AUTOSAR XML (schema 00046)
package /MICROSAR/Dcm_swc
  5 x mode declaration group:
    DcmControlDtcSetting: category=EXPLICIT_ORDER, initial-mode=ENABLEDTCSETTING, on-transition-value=2
      mode ENABLEDTCSETTING: value=0
      mode DISABLEDTCSETTING: value=1
    DcmEcuReset: category=EXPLICIT_ORDER, initial-mode=NONE, on-transition-value=7
      7 x mode:
        NONE: value=0
        HARD: value=1
        KEYONOFF: value=2
        SOFT: value=3
        JUMPTOBOOTLOADER: value=4
        JUMPTOSYSSUPPLIERBOOTLOADER: value=5
        EXECUTE: value=6
    DcmDiagnosticSessionControl: category=EXPLICIT_ORDER, initial-mode=DEFAULT_SESSION, on-transition-value=255
      4 x mode:
        DEFAULT_SESSION: value=1
        EXTENDED_SESSION: value=3
        EOLDiagnosticSession: value=96
        UFSKeepProgrammingSession: value=111
    DcmCommunicationControl: category=EXPLICIT_ORDER, initial-mode=DCM_ENABLE_RX_TX_NORM, on-transition-value=12
      12 x mode:
        DCM_ENABLE_RX_TX_NORM: value=0
        DCM_ENABLE_RX_DISABLE_TX_NORM: value=1
        DCM_DISABLE_RX_ENABLE_TX_NORM: value=2
        DCM_DISABLE_RX_TX_NORMAL: value=3
        DCM_ENABLE_RX_TX_NM: value=4
        DCM_ENABLE_RX_DISABLE_TX_NM: value=5
        DCM_DISABLE_RX_ENABLE_TX_NM: value=6
        DCM_DISABLE_RX_TX_NM: value=7
        DCM_ENABLE_RX_TX_NORM_NM: value=8
        DCM_ENABLE_RX_DISABLE_TX_NORM_NM: value=9
        DCM_DISABLE_RX_ENABLE_TX_NORM_NM: value=10
        DCM_DISABLE_RX_TX_NORM_NM: value=11
    DcmUserConditionMode: initial-mode=DCM_USER_CONDITON_NOT_OK
      mode DCM_USER_CONDITION_OK
      mode DCM_USER_CONDITON_NOT_OK
  data type mapping set DcmMappingSet  # Contains mapping for ModeDeclarationGroups which are provided by Dcm.
    mode-request-type-maps:
      implementation-data-type=Dcm_ControlDtcSettingType, mode-group=DcmControlDtcSetting
      implementation-data-type=Dcm_EcuResetType, mode-group=DcmEcuReset
      implementation-data-type=Dcm_DiagnosticSessionControlType, mode-group=DcmDiagnosticSessionControl
      implementation-data-type=Dcm_CommunicationModeType, mode-group=DcmCommunicationControl
package /MICROSAR/Dcm_swc/DataTypes
  19 x impl type:
    Dcm_ConfirmationStatusType: compu {0=DCM_RES_POS_OK, 1=DCM_RES_POS_NOT_OK, 2=DCM_RES_NEG_OK, 3=DCM_RES_NEG_NOT_OK}, range raw 0..3, implementation-data-type=uint8
    Dcm_OpStatusType: compu {0=DCM_INITIAL, 1=DCM_PENDING, 2=DCM_CANCEL, 3=DCM_FORCE_RCRRP_OK, 64=DCM_FORCE_RCRRP_NOT_OK}, range raw 0..64, implementation-data-type=uint8
    Dcm_NegativeResponseCodeType:
      compu {0=DCM_E_POSITIVERESPONSE, 16=DCM_E_GENERALREJECT, 17=DCM_E_SERVICENOTSUPPORTED, 18=DCM_E_SUBFUNCTIONNOTSUPPORTED, 19=DCM_E_INCORRECTMESSAGELENGTHORINVALIDFORMAT, 20=DCM_E_RESPONSETOOLONG, 33=DCM_E_BUSYREPEATREQUEST, 34=DCM_E_CONDITIONSNOTCORRECT, 36=DCM_E_REQUESTSEQUENCEERROR, 37=DCM_E_NORESPONSEFROMSUBNETCOMPONENT, 38=DCM_E_FAILUREPREVENTSEXECUTIONOFREQUESTEDACTION, 49=DCM_E_REQUESTOUTOFRANGE, 51=DCM_E_SECURITYACCESSDENIED, 52=DCM_E_AUTHENTICATIONREQUIRED, 53=DCM_E_INVALIDKEY, 54=DCM_E_EXCEEDNUMBEROFATTEMPTS, 55=DCM_E_REQUIREDTIMEDELAYNOTEXPIRED, 80=DCM_E_CVF_INVALIDTIMEPERIOD, 81=DCM_E_CVF_INVALIDSIGNATURE, 82=DCM_E_CVF_INVALIDCHAINOFTRUST, 83=DCM_E_CVF_INVALIDTYPE, 84=DCM_E_CVF_INVALIDFORMAT, 85=DCM_E_CVF_INVALIDCONTENT, 86=DCM_E_CVF_INVALIDSCOPE, 87=DCM_E_CVF_INVALIDCERTIFICATEREVOKED, 88=DCM_E_OWNERSHIPVERIFICATIONFAILED, 89=DCM_E_CHALLENGECALCULATIONFAILED, 112=DCM_E_UPLOADDOWNLOADNOTACCEPTED, 113=DCM_E_TRANSFERDATASUSPENDED, 114=DCM_E_GENERALPROGRAMMINGFAILURE, 115=DCM_E_WRONGBLOCKSEQUENCECOUNTER, 120=DCM_E_REQUESTCORRECTLYRECEIVEDRESPONSEPENDING, 126=DCM_E_SUBFUNCTIONNOTSUPPORTEDINACTIVESESSION, 127=DCM_E_SERVICENOTSUPPORTEDINACTIVESESSION, 129=DCM_E_RPMTOOHIGH, 130=DCM_E_RPMTOOLOW, 131=DCM_E_ENGINEISRUNNING, 132=DCM_E_ENGINEISNOTRUNNING, 133=DCM_E_ENGINERUNTIMETOOLOW, 134=DCM_E_TEMPERATURETOOHIGH, 135=DCM_E_TEMPERATURETOOLOW, 136=DCM_E_VEHICLESPEEDTOOHIGH, 137=DCM_E_VEHICLESPEEDTOOLOW, 138=DCM_E_THROTTLE_PEDALTOOHIGH, 139=DCM_E_THROTTLE_PEDALTOOLOW, 140=DCM_E_TRANSMISSIONRANGENOTINNEUTRAL, 141=DCM_E_TRANSMISSIONRANGENOTINGEAR, 143=DCM_E_BRAKESWITCH_NOTCLOSED, 144=DCM_E_SHIFTERLEVERNOTINPARK, 145=DCM_E_TORQUECONVERTERCLUTCHLOCKED, 146=DCM_E_VOLTAGETOOHIGH, 147=DCM_E_VOLTAGETOOLOW, 240..249=DCM_E_VMSCNC_0..DCM_E_VMSCNC_9, 250=DCM_E_VMSCNC_A, 251=DCM_E_VMSCNC_B, 252=DCM_E_VMSCNC_C, 253=DCM_E_VMSCNC_D, 254=DCM_E_VMSCNC_E}
      range raw 0..254
      implementation-data-type=uint8
    Dcm_ProtocolType: compu {0=DCM_OBD_ON_CAN, 1=DCM_OBD_ON_FLEXRAY, 2=DCM_OBD_ON_IP, 3=DCM_UDS_ON_CAN, 4=DCM_UDS_ON_FLEXRAY, 5=DCM_UDS_ON_IP, 12=DCM_NO_ACTIVE_PROTOCOL, 240..254=DCM_SUPPLIER_1..DCM_SUPPLIER_15}, range raw 0..254, implementation-data-type=uint8
    Dcm_RequestKindType: compu {0=DCM_REQ_KIND_NONE, 1=DCM_REQ_KIND_EXTERNAL, 2=DCM_REQ_KIND_ROE}, range raw 0..2, implementation-data-type=uint8
    Dcm_SecLevelType: compu {0=DCM_SEC_LEV_LOCKED, 1=DCM_SEC_LEV_L1, 49=DCM_SEC_LEV_L49}, range raw 0..49, implementation-data-type=uint8
    Dcm_SesCtrlType: compu {1=DCM_DEFAULT_SESSION, 3=DCM_EXTENDED_DIAGNOSTIC_SESSION, 96=DCM_EOLDiagnosticSession, 111=DCM_UFSKeepProgrammingSession}, range raw 0..111, implementation-data-type=uint8
    Dcm_ControlDtcSettingType: compu {0=DCM_ENUM_ENABLEDTCSETTING, 1=DCM_ENUM_DISABLEDTCSETTING}, range raw 0..255, implementation-data-type=uint8
    Dcm_EcuResetType: compu {0=DCM_ENUM_NONE, 1=DCM_ENUM_HARD, 2=DCM_ENUM_KEYONOFF, 3=DCM_ENUM_SOFT, 4=DCM_ENUM_JUMPTOBOOTLOADER, 5=DCM_ENUM_JUMPTOSYSSUPPLIERBOOTLOADER, 6=DCM_ENUM_EXECUTE}, range raw 0..255, implementation-data-type=uint8
    Dcm_DiagnosticSessionControlType: compu {1=DCM_ENUM_DEFAULT_SESSION, 3=DCM_ENUM_EXTENDED_SESSION, 96=DCM_ENUM_EOLDiagnosticSession, 111=DCM_ENUM_UFSKeepProgrammingSession}, range raw 0..255, implementation-data-type=uint8
    Dcm_CommunicationModeType:
      compu {0=DCM_ENABLE_RX_TX_NORM, 1=DCM_ENABLE_RX_DISABLE_TX_NORM, 2=DCM_DISABLE_RX_ENABLE_TX_NORM, 3=DCM_DISABLE_RX_TX_NORMAL, 4=DCM_ENABLE_RX_TX_NM, 5=DCM_ENABLE_RX_DISABLE_TX_NM, 6=DCM_DISABLE_RX_ENABLE_TX_NM, 7=DCM_DISABLE_RX_TX_NM, 8=DCM_ENABLE_RX_TX_NORM_NM, 9=DCM_ENABLE_RX_DISABLE_TX_NORM_NM, 10=DCM_DISABLE_RX_ENABLE_TX_NORM_NM, 11=DCM_DISABLE_RX_TX_NORM_NM}
      range raw 0..255
      implementation-data-type=uint8
    Dcm_Data4095ByteType: category=ARRAY, sw-calibration-access=READ-ONLY
      element Dcm_Data4095ByteTypeElement: array-size=4095, array-size-semantics=FIXED-SIZE, implementation-data-type=uint8
    Dcm_Data4ByteType: category=ARRAY, sw-calibration-access=READ-ONLY
      element Dcm_Data4ByteTypeElement: array-size=4, array-size-semantics=FIXED-SIZE, implementation-data-type=uint8
    Dcm_Data8ByteType: category=ARRAY, sw-calibration-access=READ-ONLY
      element Dcm_Data8ByteTypeElement: array-size=8, array-size-semantics=FIXED-SIZE, implementation-data-type=uint8
    Dcm_Data20ByteType: category=ARRAY, sw-calibration-access=READ-ONLY
      element Dcm_Data20ByteTypeElement: array-size=20, array-size-semantics=FIXED-SIZE, implementation-data-type=uint8
    Dcm_Data10ByteType: category=ARRAY, sw-calibration-access=READ-ONLY
      element Dcm_Data10ByteTypeElement: array-size=10, array-size-semantics=FIXED-SIZE, implementation-data-type=uint8
    Dcm_Data4000ByteType: category=ARRAY, sw-calibration-access=READ-ONLY
      element Dcm_Data4000ByteTypeElement: array-size=4000, array-size-semantics=FIXED-SIZE, implementation-data-type=uint8
    Dcm_DidSupportedType: compu {0=DCM_DID_SUPPORTED, 1=DCM_DID_NOT_SUPPORTED}, range raw 0..1, implementation-data-type=uint8
    Dcm_Data300ByteType: category=ARRAY, sw-calibration-access=READ-ONLY
      element Dcm_Data300ByteTypeElement: array-size=300, array-size-semantics=FIXED-SIZE, implementation-data-type=uint8
package /MICROSAR/Dcm_swc/Interfaces
  5 x mode switch interface, all with is-service=true, service-kind=DIAGNOSTIC-COMMUNICATION-MANAGER:
    DcmControlDtcSetting
      mode group DcmControlDtcSetting: type=DcmControlDtcSetting
    DcmEcuReset
      mode group DcmEcuReset: type=DcmEcuReset
    DcmDiagnosticSessionControl
      mode group DcmDiagnosticSessionControl: type=DcmDiagnosticSessionControl
    DcmCommunicationControl_ComMConf_ComMChannel_CN_B30_for_SC_CAN_V3_2_c0d6c67b
      mode group DcmCommunicationControl_ComMConf_ComMChannel_CN_B30_for_SC_CAN_V3_2_c0d6c67b: type=DcmCommunicationControl
    Dcm_Read_Mode
      mode group Dcm_Read_Mode: type=DcmUserConditionMode
  29 x client server interface, all with is-service=true, service-kind=DIAGNOSTIC-COMMUNICATION-MANAGER:
    DCMServices
      6 x operation:
        GetActiveProtocol: possible-error=E_OK
          arg ActiveProtocol: type=Dcm_ProtocolType, direction=OUT
        GetSesCtrlType: possible-error=E_OK
          arg SesCtrlType: type=Dcm_SesCtrlType, direction=OUT
        ResetToDefaultSession: possible-error=E_OK
        GetSecurityLevel: possible-error=E_OK
          arg SecLevel: type=Dcm_SecLevelType, direction=OUT
        SetActiveDiagnostic: possible-error=E_OK
          arg active: type=boolean, direction=IN
        GetRequestKind: possible-error=DCMServices/E_NOT_OK
          arg TesterSourceAddress: type=uint16, direction=IN
          arg RequestKind: type=Dcm_RequestKindType, direction=OUT
      error E_OK: error-code=0
      error E_NOT_OK: error-code=1
    ServiceRequestNotification
      operation Indication: possible-error=[ServiceRequestNotification/E_NOT_OK, E_REQUEST_NOT_ACCEPTED]
        6 x arg:
          SID: type=uint8, direction=IN
          RequestData: type=Dcm_Data4095ByteType, direction=IN
          DataSize: type=uint16, direction=IN
          ReqType: type=uint8, direction=IN
          SourceAddress: type=uint16, direction=IN
          ErrorCode: type=Dcm_NegativeResponseCodeType, direction=OUT
      operation Confirmation: possible-error=ServiceRequestNotification/E_NOT_OK
        4 x arg, all with direction=IN:
          SID: type=uint8
          ReqType: type=uint8
          SourceAddress: type=uint16
          ConfirmationStatus: type=Dcm_ConfirmationStatusType
      error E_NOT_OK: error-code=1
      error E_REQUEST_NOT_ACCEPTED: error-code=8
    SecurityAccess_UnlockedL1
      4 x operation:
        GetSeed: possible-error=[SecurityAccess_UnlockedL1/E_NOT_OK, SecurityAccess_UnlockedL1/DCM_E_PENDING]
          arg OpStatus: type=Dcm_OpStatusType, direction=IN
          arg Seed: type=Dcm_Data4ByteType, direction=OUT
          arg ErrorCode: type=Dcm_NegativeResponseCodeType, direction=OUT
        CompareKey: possible-error=[SecurityAccess_UnlockedL1/E_NOT_OK, SecurityAccess_UnlockedL1/DCM_E_PENDING, SecurityAccess_UnlockedL1/DCM_E_COMPARE_KEY_FAILED]
          arg Key: type=Dcm_Data4ByteType, direction=IN
          arg OpStatus: type=Dcm_OpStatusType, direction=IN
          arg ErrorCode: type=Dcm_NegativeResponseCodeType, direction=OUT
        GetSecurityAttemptCounter: possible-error=[SecurityAccess_UnlockedL1/E_NOT_OK, SecurityAccess_UnlockedL1/DCM_E_PENDING]
          arg OpStatus: type=Dcm_OpStatusType, direction=IN
          arg AttemptCounter: type=uint8, direction=OUT
        SetSecurityAttemptCounter: possible-error=[SecurityAccess_UnlockedL1/E_NOT_OK, SecurityAccess_UnlockedL1/DCM_E_PENDING]
          arg OpStatus: type=Dcm_OpStatusType, direction=IN
          arg AttemptCounter: type=uint8, direction=IN
      error E_NOT_OK: error-code=1
      error DCM_E_PENDING: error-code=10
      error DCM_E_COMPARE_KEY_FAILED: error-code=11
    SecurityAccess_Level_EOL_Unlocked
      4 x operation:
        GetSeed: possible-error=[SecurityAccess_Level_EOL_Unlocked/E_NOT_OK, SecurityAccess_Level_EOL_Unlocked/DCM_E_PENDING]
          arg OpStatus: type=Dcm_OpStatusType, direction=IN
          arg Seed: type=Dcm_Data4ByteType, direction=OUT
          arg ErrorCode: type=Dcm_NegativeResponseCodeType, direction=OUT
        CompareKey: possible-error=[SecurityAccess_Level_EOL_Unlocked/E_NOT_OK, SecurityAccess_Level_EOL_Unlocked/DCM_E_PENDING, SecurityAccess_Level_EOL_Unlocked/DCM_E_COMPARE_KEY_FAILED]
          arg Key: type=Dcm_Data8ByteType, direction=IN
          arg OpStatus: type=Dcm_OpStatusType, direction=IN
          arg ErrorCode: type=Dcm_NegativeResponseCodeType, direction=OUT
        GetSecurityAttemptCounter: possible-error=[SecurityAccess_Level_EOL_Unlocked/E_NOT_OK, SecurityAccess_Level_EOL_Unlocked/DCM_E_PENDING]
          arg OpStatus: type=Dcm_OpStatusType, direction=IN
          arg AttemptCounter: type=uint8, direction=OUT
        SetSecurityAttemptCounter: possible-error=[SecurityAccess_Level_EOL_Unlocked/E_NOT_OK, SecurityAccess_Level_EOL_Unlocked/DCM_E_PENDING]
          arg OpStatus: type=Dcm_OpStatusType, direction=IN
          arg AttemptCounter: type=uint8, direction=IN
      error E_NOT_OK: error-code=1
      error DCM_E_PENDING: error-code=10
      error DCM_E_COMPARE_KEY_FAILED: error-code=11
    RoutineServices_CheckEthernetIPPINGFunction
      operation Start: possible-error=[RoutineServices_CheckEthernetIPPINGFunction/E_NOT_OK, RoutineServices_CheckEthernetIPPINGFunction/DCM_E_PENDING, RoutineServices_CheckEthernetIPPINGFunction/DCM_E_FORCE_RCRRP]
        arg In_Start: type=uint32, direction=IN
        arg OpStatus: type=Dcm_OpStatusType, direction=IN
        arg ErrorCode: type=Dcm_NegativeResponseCodeType, direction=OUT
      operation RequestResults: possible-error=[RoutineServices_CheckEthernetIPPINGFunction/E_NOT_OK, RoutineServices_CheckEthernetIPPINGFunction/DCM_E_PENDING, RoutineServices_CheckEthernetIPPINGFunction/DCM_E_FORCE_RCRRP]
        arg OpStatus: type=Dcm_OpStatusType, direction=IN
        arg Out_0xF003: type=uint8, direction=OUT
        arg ErrorCode: type=Dcm_NegativeResponseCodeType, direction=OUT
      error E_NOT_OK: error-code=1
      error DCM_E_PENDING: error-code=10
      error DCM_E_FORCE_RCRRP: error-code=12
    RoutineServices_IVITouchTest
      operation Start: possible-error=[RoutineServices_IVITouchTest/E_NOT_OK, RoutineServices_IVITouchTest/DCM_E_PENDING, RoutineServices_IVITouchTest/DCM_E_FORCE_RCRRP]
        arg OpStatus: type=Dcm_OpStatusType, direction=IN
        arg Out_0xF004: type=uint8, direction=OUT
        arg ErrorCode: type=Dcm_NegativeResponseCodeType, direction=OUT
      operation RequestResults: possible-error=[RoutineServices_IVITouchTest/E_NOT_OK, RoutineServices_IVITouchTest/DCM_E_PENDING, RoutineServices_IVITouchTest/DCM_E_FORCE_RCRRP]
        arg OpStatus: type=Dcm_OpStatusType, direction=IN
        arg Out_0xF004: type=Dcm_Data20ByteType, direction=OUT
        arg ErrorCode: type=Dcm_NegativeResponseCodeType, direction=OUT
      error E_NOT_OK: error-code=1
      error DCM_E_PENDING: error-code=10
      error DCM_E_FORCE_RCRRP: error-code=12
    RoutineServices_AVMRegister
      operation Start: possible-error=[RoutineServices_AVMRegister/E_NOT_OK, RoutineServices_AVMRegister/DCM_E_PENDING, RoutineServices_AVMRegister/DCM_E_FORCE_RCRRP]
        arg OpStatus: type=Dcm_OpStatusType, direction=IN
        arg Out_AVMRegister: type=uint8, direction=OUT
        arg ErrorCode: type=Dcm_NegativeResponseCodeType, direction=OUT
      operation RequestResults: possible-error=[RoutineServices_AVMRegister/E_NOT_OK, RoutineServices_AVMRegister/DCM_E_PENDING, RoutineServices_AVMRegister/DCM_E_FORCE_RCRRP]
        arg OpStatus: type=Dcm_OpStatusType, direction=IN
        arg Out_AVMRegister: type=uint8, direction=OUT
        arg ErrorCode: type=Dcm_NegativeResponseCodeType, direction=OUT
      error E_NOT_OK: error-code=1
      error DCM_E_PENDING: error-code=10
      error DCM_E_FORCE_RCRRP: error-code=12
    RoutineServices_AMPCalibration
      operation Start: possible-error=[RoutineServices_AMPCalibration/E_NOT_OK, RoutineServices_AMPCalibration/DCM_E_PENDING, RoutineServices_AMPCalibration/DCM_E_FORCE_RCRRP]
        arg OpStatus: type=Dcm_OpStatusType, direction=IN
        arg Out_RoutineStatusRecord: type=uint8, direction=OUT
        arg ErrorCode: type=Dcm_NegativeResponseCodeType, direction=OUT
      operation RequestResults: possible-error=[RoutineServices_AMPCalibration/E_NOT_OK, RoutineServices_AMPCalibration/DCM_E_PENDING, RoutineServices_AMPCalibration/DCM_E_FORCE_RCRRP]
        arg OpStatus: type=Dcm_OpStatusType, direction=IN
        arg Out_AmpValue: type=Dcm_Data10ByteType, direction=OUT
        arg ErrorCode: type=Dcm_NegativeResponseCodeType, direction=OUT
      error E_NOT_OK: error-code=1
      error DCM_E_PENDING: error-code=10
      error DCM_E_FORCE_RCRRP: error-code=12
    RoutineServices_PhyTestMode
      operation Start: possible-error=[RoutineServices_PhyTestMode/E_NOT_OK, RoutineServices_PhyTestMode/DCM_E_PENDING, RoutineServices_PhyTestMode/DCM_E_FORCE_RCRRP]
        4 x arg:
          In_PortNumber: type=uint8, direction=IN
          In_TestMode: type=uint8, direction=IN
          OpStatus: type=Dcm_OpStatusType, direction=IN
          ErrorCode: type=Dcm_NegativeResponseCodeType, direction=OUT
      error E_NOT_OK: error-code=1
      error DCM_E_PENDING: error-code=10
      error DCM_E_FORCE_RCRRP: error-code=12
    RoutineServices_CableDiagnostics
      operation Start: possible-error=[RoutineServices_CableDiagnostics/E_NOT_OK, RoutineServices_CableDiagnostics/DCM_E_PENDING, RoutineServices_CableDiagnostics/DCM_E_FORCE_RCRRP]
        4 x arg:
          In_CableDiagnosticsControl: type=uint8, direction=IN
          OpStatus: type=Dcm_OpStatusType, direction=IN
          Out_Result: type=uint8, direction=OUT
          ErrorCode: type=Dcm_NegativeResponseCodeType, direction=OUT
      error E_NOT_OK: error-code=1
      error DCM_E_PENDING: error-code=10
      error DCM_E_FORCE_RCRRP: error-code=12
    RoutineServices_ResetSwitchStatistics
      operation Start: possible-error=[RoutineServices_ResetSwitchStatistics/E_NOT_OK, RoutineServices_ResetSwitchStatistics/DCM_E_PENDING, RoutineServices_ResetSwitchStatistics/DCM_E_FORCE_RCRRP]
        arg OpStatus: type=Dcm_OpStatusType, direction=IN
        arg ErrorCode: type=Dcm_NegativeResponseCodeType, direction=OUT
      error E_NOT_OK: error-code=1
      error DCM_E_PENDING: error-code=10
      error DCM_E_FORCE_RCRRP: error-code=12
    RoutineServices_AVMEnvironmentCheck
      operation Start: possible-error=[RoutineServices_AVMEnvironmentCheck/E_NOT_OK, RoutineServices_AVMEnvironmentCheck/DCM_E_PENDING, RoutineServices_AVMEnvironmentCheck/DCM_E_FORCE_RCRRP]
        arg OpStatus: type=Dcm_OpStatusType, direction=IN
        arg ErrorCode: type=Dcm_NegativeResponseCodeType, direction=OUT
      operation RequestResults: possible-error=[RoutineServices_AVMEnvironmentCheck/E_NOT_OK, RoutineServices_AVMEnvironmentCheck/DCM_E_PENDING, RoutineServices_AVMEnvironmentCheck/DCM_E_FORCE_RCRRP]
        arg OpStatus: type=Dcm_OpStatusType, direction=IN
        arg Out_AVMEnvironmentCheckResult: type=uint8, direction=OUT
        arg ErrorCode: type=Dcm_NegativeResponseCodeType, direction=OUT
      error E_NOT_OK: error-code=1
      error DCM_E_PENDING: error-code=10
      error DCM_E_FORCE_RCRRP: error-code=12
    RoutineServices_AVMAutoCalibration
      operation Start: possible-error=[RoutineServices_AVMAutoCalibration/E_NOT_OK, RoutineServices_AVMAutoCalibration/DCM_E_PENDING, RoutineServices_AVMAutoCalibration/DCM_E_FORCE_RCRRP]
        arg OpStatus: type=Dcm_OpStatusType, direction=IN
        arg ErrorCode: type=Dcm_NegativeResponseCodeType, direction=OUT
      operation RequestResults: possible-error=[RoutineServices_AVMAutoCalibration/E_NOT_OK, RoutineServices_AVMAutoCalibration/DCM_E_PENDING, RoutineServices_AVMAutoCalibration/DCM_E_FORCE_RCRRP]
        arg OpStatus: type=Dcm_OpStatusType, direction=IN
        arg Out_AVMCalibrationResult: type=uint8, direction=OUT
        arg ErrorCode: type=Dcm_NegativeResponseCodeType, direction=OUT
      error E_NOT_OK: error-code=1
      error DCM_E_PENDING: error-code=10
      error DCM_E_FORCE_RCRRP: error-code=12
    RoutineServices_AVMManualCalibration
      operation Start: possible-error=[RoutineServices_AVMManualCalibration/E_NOT_OK, RoutineServices_AVMManualCalibration/DCM_E_PENDING, RoutineServices_AVMManualCalibration/DCM_E_FORCE_RCRRP]
        arg OpStatus: type=Dcm_OpStatusType, direction=IN
        arg ErrorCode: type=Dcm_NegativeResponseCodeType, direction=OUT
      operation Stop: possible-error=[RoutineServices_AVMManualCalibration/E_NOT_OK, RoutineServices_AVMManualCalibration/DCM_E_PENDING, RoutineServices_AVMManualCalibration/DCM_E_FORCE_RCRRP]
        arg OpStatus: type=Dcm_OpStatusType, direction=IN
        arg ErrorCode: type=Dcm_NegativeResponseCodeType, direction=OUT
      operation RequestResults: possible-error=[RoutineServices_AVMManualCalibration/E_NOT_OK, RoutineServices_AVMManualCalibration/DCM_E_PENDING, RoutineServices_AVMManualCalibration/DCM_E_FORCE_RCRRP]
        arg OpStatus: type=Dcm_OpStatusType, direction=IN
        arg Out_ManualCalibrationResult: type=uint8, direction=OUT
        arg ErrorCode: type=Dcm_NegativeResponseCodeType, direction=OUT
      error E_NOT_OK: error-code=1
      error DCM_E_PENDING: error-code=10
      error DCM_E_FORCE_RCRRP: error-code=12
    RoutineServices_AVMManualViewSelect
      operation Start: possible-error=[RoutineServices_AVMManualViewSelect/E_NOT_OK, RoutineServices_AVMManualViewSelect/DCM_E_PENDING, RoutineServices_AVMManualViewSelect/DCM_E_FORCE_RCRRP]
        arg In_AVMManualViewSelect: type=uint8, direction=IN
        arg OpStatus: type=Dcm_OpStatusType, direction=IN
        arg ErrorCode: type=Dcm_NegativeResponseCodeType, direction=OUT
      operation RequestResults: possible-error=[RoutineServices_AVMManualViewSelect/E_NOT_OK, RoutineServices_AVMManualViewSelect/DCM_E_PENDING, RoutineServices_AVMManualViewSelect/DCM_E_FORCE_RCRRP]
        arg OpStatus: type=Dcm_OpStatusType, direction=IN
        arg Out_AVMEnvironmentCheckResult: type=uint8, direction=OUT
        arg ErrorCode: type=Dcm_NegativeResponseCodeType, direction=OUT
      error E_NOT_OK: error-code=1
      error DCM_E_PENDING: error-code=10
      error DCM_E_FORCE_RCRRP: error-code=12
    RoutineServices_AVMManualConerSelect
      operation Start: possible-error=[RoutineServices_AVMManualConerSelect/E_NOT_OK, RoutineServices_AVMManualConerSelect/DCM_E_PENDING, RoutineServices_AVMManualConerSelect/DCM_E_FORCE_RCRRP]
        arg In_AVMManualConerSelect: type=uint8, direction=IN
        arg OpStatus: type=Dcm_OpStatusType, direction=IN
        arg ErrorCode: type=Dcm_NegativeResponseCodeType, direction=OUT
      operation RequestResults: possible-error=[RoutineServices_AVMManualConerSelect/E_NOT_OK, RoutineServices_AVMManualConerSelect/DCM_E_PENDING, RoutineServices_AVMManualConerSelect/DCM_E_FORCE_RCRRP]
        arg OpStatus: type=Dcm_OpStatusType, direction=IN
        arg Out_AVMEnvironmentCheckResult: type=uint8, direction=OUT
        arg ErrorCode: type=Dcm_NegativeResponseCodeType, direction=OUT
      error E_NOT_OK: error-code=1
      error DCM_E_PENDING: error-code=10
      error DCM_E_FORCE_RCRRP: error-code=12
    RoutineServices_AVMManualConerMove
      operation Start: possible-error=[RoutineServices_AVMManualConerMove/E_NOT_OK, RoutineServices_AVMManualConerMove/DCM_E_PENDING, RoutineServices_AVMManualConerMove/DCM_E_FORCE_RCRRP]
        arg In_AVMManualConerMove: type=uint8, direction=IN
        arg OpStatus: type=Dcm_OpStatusType, direction=IN
        arg ErrorCode: type=Dcm_NegativeResponseCodeType, direction=OUT
      operation RequestResults: possible-error=[RoutineServices_AVMManualConerMove/E_NOT_OK, RoutineServices_AVMManualConerMove/DCM_E_PENDING, RoutineServices_AVMManualConerMove/DCM_E_FORCE_RCRRP]
        arg OpStatus: type=Dcm_OpStatusType, direction=IN
        arg Out_AVMManualConerMoveResult: type=uint8, direction=OUT
        arg ErrorCode: type=Dcm_NegativeResponseCodeType, direction=OUT
      error E_NOT_OK: error-code=1
      error DCM_E_PENDING: error-code=10
      error DCM_E_FORCE_RCRRP: error-code=12
    RoutineServices_AVMManualCorrectValue
      operation Start: possible-error=[RoutineServices_AVMManualCorrectValue/E_NOT_OK, RoutineServices_AVMManualCorrectValue/DCM_E_PENDING, RoutineServices_AVMManualCorrectValue/DCM_E_FORCE_RCRRP]
        arg OpStatus: type=Dcm_OpStatusType, direction=IN
        arg ErrorCode: type=Dcm_NegativeResponseCodeType, direction=OUT
      operation RequestResults: possible-error=[RoutineServices_AVMManualCorrectValue/E_NOT_OK, RoutineServices_AVMManualCorrectValue/DCM_E_PENDING, RoutineServices_AVMManualCorrectValue/DCM_E_FORCE_RCRRP]
        arg OpStatus: type=Dcm_OpStatusType, direction=IN
        arg Out_AVMManualCorrectValue: type=uint8, direction=OUT
        arg ErrorCode: type=Dcm_NegativeResponseCodeType, direction=OUT
      error E_NOT_OK: error-code=1
      error DCM_E_PENDING: error-code=10
      error DCM_E_FORCE_RCRRP: error-code=12
    RoutineServices_SystemRecovery
      operation Start: possible-error=[RoutineServices_SystemRecovery/E_NOT_OK, RoutineServices_SystemRecovery/DCM_E_PENDING, RoutineServices_SystemRecovery/DCM_E_FORCE_RCRRP]
        arg OpStatus: type=Dcm_OpStatusType, direction=IN
        arg Out_SystemRcvrySts: type=uint8, direction=OUT
        arg ErrorCode: type=Dcm_NegativeResponseCodeType, direction=OUT
      error E_NOT_OK: error-code=1
      error DCM_E_PENDING: error-code=10
      error DCM_E_FORCE_RCRRP: error-code=12
    RoutineServices_ODOReset
      operation Start: possible-error=[RoutineServices_ODOReset/E_NOT_OK, RoutineServices_ODOReset/DCM_E_PENDING, RoutineServices_ODOReset/DCM_E_FORCE_RCRRP]
        arg OpStatus: type=Dcm_OpStatusType, direction=IN
        arg ErrorCode: type=Dcm_NegativeResponseCodeType, direction=OUT
      operation RequestResults: possible-error=[RoutineServices_ODOReset/E_NOT_OK, RoutineServices_ODOReset/DCM_E_PENDING, RoutineServices_ODOReset/DCM_E_FORCE_RCRRP]
        arg OpStatus: type=Dcm_OpStatusType, direction=IN
        arg Out_OdoResetResult: type=uint8, direction=OUT
        arg ErrorCode: type=Dcm_NegativeResponseCodeType, direction=OUT
      error E_NOT_OK: error-code=1
      error DCM_E_PENDING: error-code=10
      error DCM_E_FORCE_RCRRP: error-code=12
    DataServices_VehicleModel_VehicleModel
      operation ReadData: possible-error=[DataServices_VehicleModel_VehicleModel/E_NOT_OK, DataServices_VehicleModel_VehicleModel/DCM_E_PENDING]
        arg OpStatus: type=Dcm_OpStatusType, direction=IN
        arg Data: type=Dcm_Data20ByteType, direction=OUT
      operation ConditionCheckRead: possible-error=[DataServices_VehicleModel_VehicleModel/E_NOT_OK, DataServices_VehicleModel_VehicleModel/DCM_E_PENDING]
        arg OpStatus: type=Dcm_OpStatusType, direction=IN
        arg ErrorCode: type=Dcm_NegativeResponseCodeType, direction=OUT
      operation WriteData: possible-error=[DataServices_VehicleModel_VehicleModel/E_NOT_OK, DataServices_VehicleModel_VehicleModel/DCM_E_PENDING]
        arg Data: type=Dcm_Data20ByteType, direction=IN
        arg OpStatus: type=Dcm_OpStatusType, direction=IN
        arg ErrorCode: type=Dcm_NegativeResponseCodeType, direction=OUT
      error E_NOT_OK: error-code=1
      error DCM_E_PENDING: error-code=10
    RoutineServices_ConfigureFrontCamerParameters
      operation Start: possible-error=[RoutineServices_ConfigureFrontCamerParameters/E_NOT_OK, RoutineServices_ConfigureFrontCamerParameters/DCM_E_PENDING, RoutineServices_ConfigureFrontCamerParameters/DCM_E_FORCE_RCRRP]
        arg OpStatus: type=Dcm_OpStatusType, direction=IN
        arg ErrorCode: type=Dcm_NegativeResponseCodeType, direction=OUT
      operation RequestResults: possible-error=[RoutineServices_ConfigureFrontCamerParameters/E_NOT_OK, RoutineServices_ConfigureFrontCamerParameters/DCM_E_PENDING, RoutineServices_ConfigureFrontCamerParameters/DCM_E_FORCE_RCRRP]
        arg OpStatus: type=Dcm_OpStatusType, direction=IN
        arg DcmDspRoutineRequestResOutSignal: type=uint8, direction=OUT
        arg ErrorCode: type=Dcm_NegativeResponseCodeType, direction=OUT
      error E_NOT_OK: error-code=1
      error DCM_E_PENDING: error-code=10
      error DCM_E_FORCE_RCRRP: error-code=12
    RoutineServices_ConfigureRearCamerParameters
      operation Start: possible-error=[RoutineServices_ConfigureRearCamerParameters/E_NOT_OK, RoutineServices_ConfigureRearCamerParameters/DCM_E_PENDING, RoutineServices_ConfigureRearCamerParameters/DCM_E_FORCE_RCRRP]
        arg OpStatus: type=Dcm_OpStatusType, direction=IN
        arg ErrorCode: type=Dcm_NegativeResponseCodeType, direction=OUT
      operation RequestResults: possible-error=[RoutineServices_ConfigureRearCamerParameters/E_NOT_OK, RoutineServices_ConfigureRearCamerParameters/DCM_E_PENDING, RoutineServices_ConfigureRearCamerParameters/DCM_E_FORCE_RCRRP]
        arg OpStatus: type=Dcm_OpStatusType, direction=IN
        arg DcmDspRoutineRequestResOutSignal: type=uint8, direction=OUT
        arg ErrorCode: type=Dcm_NegativeResponseCodeType, direction=OUT
      error E_NOT_OK: error-code=1
      error DCM_E_PENDING: error-code=10
      error DCM_E_FORCE_RCRRP: error-code=12
    RoutineServices_ConfigureLeftCamerParameters
      operation Start: possible-error=[RoutineServices_ConfigureLeftCamerParameters/E_NOT_OK, RoutineServices_ConfigureLeftCamerParameters/DCM_E_PENDING, RoutineServices_ConfigureLeftCamerParameters/DCM_E_FORCE_RCRRP]
        arg OpStatus: type=Dcm_OpStatusType, direction=IN
        arg ErrorCode: type=Dcm_NegativeResponseCodeType, direction=OUT
      operation RequestResults: possible-error=[RoutineServices_ConfigureLeftCamerParameters/E_NOT_OK, RoutineServices_ConfigureLeftCamerParameters/DCM_E_PENDING, RoutineServices_ConfigureLeftCamerParameters/DCM_E_FORCE_RCRRP]
        arg OpStatus: type=Dcm_OpStatusType, direction=IN
        arg DcmDspRoutineRequestResOutSignal: type=uint8, direction=OUT
        arg ErrorCode: type=Dcm_NegativeResponseCodeType, direction=OUT
      error E_NOT_OK: error-code=1
      error DCM_E_PENDING: error-code=10
      error DCM_E_FORCE_RCRRP: error-code=12
    RoutineServices_ConfigureRightCamerParameters
      operation Start: possible-error=[RoutineServices_ConfigureRightCamerParameters/E_NOT_OK, RoutineServices_ConfigureRightCamerParameters/DCM_E_PENDING, RoutineServices_ConfigureRightCamerParameters/DCM_E_FORCE_RCRRP]
        arg OpStatus: type=Dcm_OpStatusType, direction=IN
        arg ErrorCode: type=Dcm_NegativeResponseCodeType, direction=OUT
      operation RequestResults: possible-error=[RoutineServices_ConfigureRightCamerParameters/E_NOT_OK, RoutineServices_ConfigureRightCamerParameters/DCM_E_PENDING, RoutineServices_ConfigureRightCamerParameters/DCM_E_FORCE_RCRRP]
        arg OpStatus: type=Dcm_OpStatusType, direction=IN
        arg DcmDspRoutineRequestResOutSignal: type=uint8, direction=OUT
        arg ErrorCode: type=Dcm_NegativeResponseCodeType, direction=OUT
      error E_NOT_OK: error-code=1
      error DCM_E_PENDING: error-code=10
      error DCM_E_FORCE_RCRRP: error-code=12
    DataServices_DIDRange_DidRangeEol1
      operation ReadDidData: possible-error=[DataServices_DIDRange_DidRangeEol1/E_NOT_OK, DataServices_DIDRange_DidRangeEol1/DCM_E_PENDING]
        5 x arg:
          DID: type=uint16, direction=IN
          Data: type=Dcm_Data4000ByteType, direction=OUT
          OpStatus: type=Dcm_OpStatusType, direction=IN
          DataLength: type=uint16, direction=OUT
          ErrorCode: type=Dcm_NegativeResponseCodeType, direction=OUT
      operation WriteDidData: possible-error=[DataServices_DIDRange_DidRangeEol1/E_NOT_OK, DataServices_DIDRange_DidRangeEol1/DCM_E_PENDING]
        5 x arg:
          DID: type=uint16, direction=IN
          Data: type=Dcm_Data4000ByteType, direction=IN
          OpStatus: type=Dcm_OpStatusType, direction=IN
          DataLength: type=uint16, direction=IN
          ErrorCode: type=Dcm_NegativeResponseCodeType, direction=OUT
      operation IsDidAvailable: possible-error=[DataServices_DIDRange_DidRangeEol1/E_NOT_OK, DataServices_DIDRange_DidRangeEol1/DCM_E_PENDING]
        arg DID: type=uint16, direction=IN
        arg OpStatus: type=Dcm_OpStatusType, direction=IN
        arg supported: type=Dcm_DidSupportedType, direction=OUT
      error E_NOT_OK: error-code=1
      error DCM_E_PENDING: error-code=10
    DataServices_DIDRange_DidRangeDiag1
      operation ReadDidData: possible-error=[DataServices_DIDRange_DidRangeDiag1/E_NOT_OK, DataServices_DIDRange_DidRangeDiag1/DCM_E_PENDING]
        5 x arg:
          DID: type=uint16, direction=IN
          Data: type=Dcm_Data4000ByteType, direction=OUT
          OpStatus: type=Dcm_OpStatusType, direction=IN
          DataLength: type=uint16, direction=OUT
          ErrorCode: type=Dcm_NegativeResponseCodeType, direction=OUT
      operation WriteDidData: possible-error=[DataServices_DIDRange_DidRangeDiag1/E_NOT_OK, DataServices_DIDRange_DidRangeDiag1/DCM_E_PENDING]
        5 x arg:
          DID: type=uint16, direction=IN
          Data: type=Dcm_Data4000ByteType, direction=IN
          OpStatus: type=Dcm_OpStatusType, direction=IN
          DataLength: type=uint16, direction=IN
          ErrorCode: type=Dcm_NegativeResponseCodeType, direction=OUT
      operation IsDidAvailable: possible-error=[DataServices_DIDRange_DidRangeDiag1/E_NOT_OK, DataServices_DIDRange_DidRangeDiag1/DCM_E_PENDING]
        arg DID: type=uint16, direction=IN
        arg OpStatus: type=Dcm_OpStatusType, direction=IN
        arg supported: type=Dcm_DidSupportedType, direction=OUT
      error E_NOT_OK: error-code=1
      error DCM_E_PENDING: error-code=10
    DataServices_DIDRange_DidRangeDiag2
      operation ReadDidData: possible-error=[DataServices_DIDRange_DidRangeDiag2/E_NOT_OK, DataServices_DIDRange_DidRangeDiag2/DCM_E_PENDING]
        5 x arg:
          DID: type=uint16, direction=IN
          Data: type=Dcm_Data300ByteType, direction=OUT
          OpStatus: type=Dcm_OpStatusType, direction=IN
          DataLength: type=uint16, direction=OUT
          ErrorCode: type=Dcm_NegativeResponseCodeType, direction=OUT
      operation WriteDidData: possible-error=[DataServices_DIDRange_DidRangeDiag2/E_NOT_OK, DataServices_DIDRange_DidRangeDiag2/DCM_E_PENDING]
        5 x arg:
          DID: type=uint16, direction=IN
          Data: type=Dcm_Data300ByteType, direction=IN
          OpStatus: type=Dcm_OpStatusType, direction=IN
          DataLength: type=uint16, direction=IN
          ErrorCode: type=Dcm_NegativeResponseCodeType, direction=OUT
      operation IsDidAvailable: possible-error=[DataServices_DIDRange_DidRangeDiag2/E_NOT_OK, DataServices_DIDRange_DidRangeDiag2/DCM_E_PENDING]
        arg DID: type=uint16, direction=IN
        arg OpStatus: type=Dcm_OpStatusType, direction=IN
        arg supported: type=Dcm_DidSupportedType, direction=OUT
      error E_NOT_OK: error-code=1
      error DCM_E_PENDING: error-code=10
    RoutineServices_RequestCertificateStatus
      operation Start: possible-error=[RoutineServices_RequestCertificateStatus/E_NOT_OK, RoutineServices_RequestCertificateStatus/DCM_E_PENDING, RoutineServices_RequestCertificateStatus/DCM_E_FORCE_RCRRP]
        arg OpStatus: type=Dcm_OpStatusType, direction=IN
        arg ErrorCode: type=Dcm_NegativeResponseCodeType, direction=OUT
      operation RequestResults: possible-error=[RoutineServices_RequestCertificateStatus/E_NOT_OK, RoutineServices_RequestCertificateStatus/DCM_E_PENDING, RoutineServices_RequestCertificateStatus/DCM_E_FORCE_RCRRP]
        arg OpStatus: type=Dcm_OpStatusType, direction=IN
        arg DcmDspRoutineRequestResOutSignal: type=uint8, direction=OUT
        arg ErrorCode: type=Dcm_NegativeResponseCodeType, direction=OUT
      error E_NOT_OK: error-code=1
      error DCM_E_PENDING: error-code=10
      error DCM_E_FORCE_RCRRP: error-code=12
package /MICROSAR/Dcm_swc/ComponentTypes
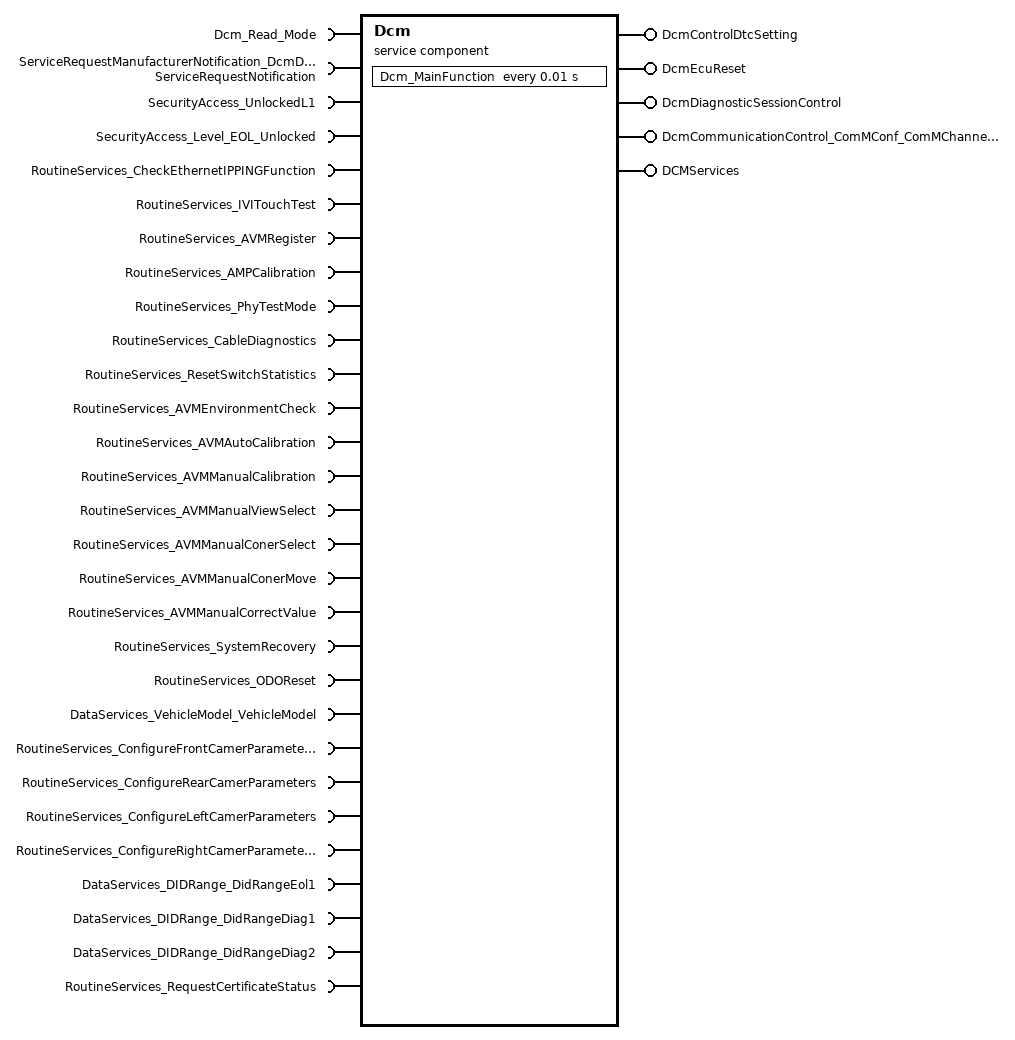
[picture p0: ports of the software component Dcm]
  service sw component type Dcm: category=SERVICE_COMPONENT
    4 x provide port:
      DcmControlDtcSetting: provided-interface=DcmControlDtcSetting
      DcmEcuReset: mode-switch-sender-com-spec{mode-group=DcmEcuReset, mode-switched-ack=timeout=0}, provided-interface=DcmEcuReset
      DcmDiagnosticSessionControl: provided-interface=DcmDiagnosticSessionControl
      DcmCommunicationControl_ComMConf_ComMChannel_CN_B30_for_SC_CAN_V3_2_c0d6c67b: provided-interface=DcmCommunicationControl_ComMConf_ComMChannel_CN_B30_for_SC_CAN_V3_2_c0d6c67b
    require port Dcm_Read_Mode: mode-switch-receiver-com-spec=enhanced-mode-api=true, required-interface=Dcm_Read_Mode
    provide port DCMServices: provided-interface=DCMServices
    28 x require port:
      ServiceRequestManufacturerNotification_DcmDslServiceRequestGWMNotification: required-interface=ServiceRequestNotification
      SecurityAccess_UnlockedL1: required-interface=SecurityAccess_UnlockedL1
      SecurityAccess_Level_EOL_Unlocked: required-interface=SecurityAccess_Level_EOL_Unlocked
      RoutineServices_CheckEthernetIPPINGFunction: required-interface=RoutineServices_CheckEthernetIPPINGFunction
      RoutineServices_IVITouchTest: required-interface=RoutineServices_IVITouchTest
      RoutineServices_AVMRegister: required-interface=RoutineServices_AVMRegister
      RoutineServices_AMPCalibration: required-interface=RoutineServices_AMPCalibration
      RoutineServices_PhyTestMode: required-interface=RoutineServices_PhyTestMode
      RoutineServices_CableDiagnostics: required-interface=RoutineServices_CableDiagnostics
      RoutineServices_ResetSwitchStatistics: required-interface=RoutineServices_ResetSwitchStatistics
      RoutineServices_AVMEnvironmentCheck: required-interface=RoutineServices_AVMEnvironmentCheck
      RoutineServices_AVMAutoCalibration: required-interface=RoutineServices_AVMAutoCalibration
      RoutineServices_AVMManualCalibration: required-interface=RoutineServices_AVMManualCalibration
      RoutineServices_AVMManualViewSelect: required-interface=RoutineServices_AVMManualViewSelect
      RoutineServices_AVMManualConerSelect: required-interface=RoutineServices_AVMManualConerSelect
      RoutineServices_AVMManualConerMove: required-interface=RoutineServices_AVMManualConerMove
      RoutineServices_AVMManualCorrectValue: required-interface=RoutineServices_AVMManualCorrectValue
      RoutineServices_SystemRecovery: required-interface=RoutineServices_SystemRecovery
      RoutineServices_ODOReset: required-interface=RoutineServices_ODOReset
      DataServices_VehicleModel_VehicleModel: required-interface=DataServices_VehicleModel_VehicleModel
      RoutineServices_ConfigureFrontCamerParameters: required-interface=RoutineServices_ConfigureFrontCamerParameters
      RoutineServices_ConfigureRearCamerParameters: required-interface=RoutineServices_ConfigureRearCamerParameters
      RoutineServices_ConfigureLeftCamerParameters: required-interface=RoutineServices_ConfigureLeftCamerParameters
      RoutineServices_ConfigureRightCamerParameters: required-interface=RoutineServices_ConfigureRightCamerParameters
      DataServices_DIDRange_DidRangeEol1: required-interface=DataServices_DIDRange_DidRangeEol1
      DataServices_DIDRange_DidRangeDiag1: required-interface=DataServices_DIDRange_DidRangeDiag1
      DataServices_DIDRange_DidRangeDiag2: required-interface=DataServices_DIDRange_DidRangeDiag2
      RoutineServices_RequestCertificateStatus: required-interface=RoutineServices_RequestCertificateStatus
    behavior DcmInternalBehavior: data-type-mapping=DcmMappingSet, handle-termination-and-restart=NO-SUPPORT, included-data-type-set=data-type=[Dcm_ConfirmationStatusType, Dcm_OpStatusType, Dcm_DidSupportedType, Dcm_NegativeResponseCodeType, Dcm_ProtocolType, Dcm_RequestKindType, Dcm_SecLevelType, Dcm_SesCtrlType, Dcm_ControlDtcSettingType, Dcm_EcuResetType, Dcm_DiagnosticSessionControlType, Dcm_CommunicationModeType]
      timing event Timer_Dcm_MainFunction: start-on-event=Dcm_MainFunction, period=0.01
      6 x operation invoked event:
        OpEventGetActiveProtocol_GetActiveProtocol_DCMServices: start-on-event=GetActiveProtocol, operation=DCMServices.GetActiveProtocol
        OpEventGetSesCtrlType_GetSesCtrlType_DCMServices: start-on-event=GetSesCtrlType, operation=DCMServices.GetSesCtrlType
        OpEventResetToDefaultSession_ResetToDefaultSession_DCMServices: start-on-event=ResetToDefaultSession, operation=DCMServices.ResetToDefaultSession
        OpEventGetSecurityLevel_GetSecurityLevel_DCMServices: start-on-event=GetSecurityLevel, operation=DCMServices.GetSecurityLevel
        OpEventSetActiveDiagnostic_SetActiveDiagnostic_DCMServices: start-on-event=SetActiveDiagnostic, operation=DCMServices.SetActiveDiagnostic
        OpEventGetRequestKind_GetRequestKind_DCMServices: start-on-event=GetRequestKind, operation=DCMServices.GetRequestKind
      port-api-options:
        enable-take-address=true, indirect-api=false, port=DcmControlDtcSetting
        enable-take-address=true, indirect-api=false, port=DcmEcuReset
        enable-take-address=true, indirect-api=false, port=DcmDiagnosticSessionControl
        enable-take-address=true, indirect-api=false, port=DcmCommunicationControl_ComMConf_ComMChannel_CN_B30_for_SC_CAN_V3_2_c0d6c67b
        enable-take-address=true, indirect-api=false, port=Dcm_Read_Mode
        enable-take-address=true, indirect-api=false, port=DCMServices
        enable-take-address=true, indirect-api=false, port=ServiceRequestManufacturerNotification_DcmDslServiceRequestGWMNotification
        enable-take-address=true, indirect-api=false, port=SecurityAccess_UnlockedL1
        enable-take-address=true, indirect-api=false, port=SecurityAccess_Level_EOL_Unlocked
        enable-take-address=true, indirect-api=false, port=RoutineServices_CheckEthernetIPPINGFunction
        enable-take-address=true, indirect-api=false, port=RoutineServices_IVITouchTest
        enable-take-address=true, indirect-api=false, port=RoutineServices_AVMRegister
        enable-take-address=true, indirect-api=false, port=RoutineServices_AMPCalibration
        enable-take-address=true, indirect-api=false, port=RoutineServices_PhyTestMode
        enable-take-address=true, indirect-api=false, port=RoutineServices_CableDiagnostics
        enable-take-address=true, indirect-api=false, port=RoutineServices_ResetSwitchStatistics
        enable-take-address=true, indirect-api=false, port=RoutineServices_ConfigureFrontCamerParameters
        enable-take-address=true, indirect-api=false, port=RoutineServices_ConfigureRearCamerParameters
        enable-take-address=true, indirect-api=false, port=RoutineServices_ConfigureLeftCamerParameters
        enable-take-address=true, indirect-api=false, port=RoutineServices_ConfigureRightCamerParameters
        enable-take-address=true, indirect-api=false, port=RoutineServices_AVMEnvironmentCheck
        enable-take-address=true, indirect-api=false, port=RoutineServices_AVMAutoCalibration
        enable-take-address=true, indirect-api=false, port=RoutineServices_AVMManualCalibration
        enable-take-address=true, indirect-api=false, port=RoutineServices_AVMManualViewSelect
        enable-take-address=true, indirect-api=false, port=RoutineServices_AVMManualConerSelect
        enable-take-address=true, indirect-api=false, port=RoutineServices_AVMManualConerMove
        enable-take-address=true, indirect-api=false, port=RoutineServices_AVMManualCorrectValue
        enable-take-address=true, indirect-api=false, port=RoutineServices_SystemRecovery
        enable-take-address=true, indirect-api=false, port=RoutineServices_ODOReset
        enable-take-address=true, indirect-api=false, port=DataServices_VehicleModel_VehicleModel
        enable-take-address=true, indirect-api=false, port=DataServices_DIDRange_DidRangeEol1
        enable-take-address=true, indirect-api=false, port=DataServices_DIDRange_DidRangeDiag1
        enable-take-address=true, indirect-api=false, port=DataServices_DIDRange_DidRangeDiag2
        enable-take-address=true, indirect-api=false, port=RoutineServices_RequestCertificateStatus
      7 x runnable:
        Dcm_MainFunction: mode-access-point=Dcm_Read_Mode.Dcm_Read_Mode
          4 x mode switch point:
            ModeSwitchPointDcm_MainFunction_DcmControlDtcSetting_DcmControlDtcSetting: mode-group=DcmControlDtcSetting.DcmControlDtcSetting
            ModeSwitchPointDcm_MainFunction_DcmEcuReset_DcmEcuReset: mode-group=DcmEcuReset.DcmEcuReset
            ModeSwitchPointDcm_MainFunction_DcmDiagnosticSessionControl_DcmDiagnosticSessionControl: mode-group=DcmDiagnosticSessionControl.DcmDiagnosticSessionControl
            ModeSwitchPointDcm_MainFunction_DcmCommunicationControl_ComMConf_ComMChannel_CN_B30_for_SC_CAN_V3_2_c0d6c67b_DcmCommuni_d74ea8a3: mode-group=DcmCommunicationControl_ComMConf_ComMChannel_CN_B30_for_SC_CAN_V3_2_c0d6c67b.DcmCommunicationControl_ComMConf_ComMChannel_CN_B30_for_SC_CAN_V3_2_c0d6c67b
          61 x sync call, all with timeout=0:
            OpServerCallDcm_MainFunction_Indication_ServiceRequestManufacturerNotification_DcmDslServiceRequestGWMNotification: operation=ServiceRequestManufacturerNotification_DcmDslServiceRequestGWMNotification.Indication
            OpServerCallDcm_MainFunction_Confirmation_ServiceRequestManufacturerNotification_DcmDslServiceRequestGWMNotification: operation=ServiceRequestManufacturerNotification_DcmDslServiceRequestGWMNotification.Confirmation
            OpServerCallDcm_MainFunction_GetSeed_SecurityAccess_UnlockedL1: operation=SecurityAccess_UnlockedL1.GetSeed
            OpServerCallDcm_MainFunction_CompareKey_SecurityAccess_UnlockedL1: operation=SecurityAccess_UnlockedL1.CompareKey
            OpServerCallDcm_MainFunction_GetSecurityAttemptCounter_SecurityAccess_UnlockedL1: operation=SecurityAccess_UnlockedL1.GetSecurityAttemptCounter
            OpServerCallDcm_MainFunction_SetSecurityAttemptCounter_SecurityAccess_UnlockedL1: operation=SecurityAccess_UnlockedL1.SetSecurityAttemptCounter
            OpServerCallDcm_MainFunction_GetSeed_SecurityAccess_Level_EOL_Unlocked: operation=SecurityAccess_Level_EOL_Unlocked.GetSeed
            OpServerCallDcm_MainFunction_CompareKey_SecurityAccess_Level_EOL_Unlocked: operation=SecurityAccess_Level_EOL_Unlocked.CompareKey
            OpServerCallDcm_MainFunction_GetSecurityAttemptCounter_SecurityAccess_Level_EOL_Unlocked: operation=SecurityAccess_Level_EOL_Unlocked.GetSecurityAttemptCounter
            OpServerCallDcm_MainFunction_SetSecurityAttemptCounter_SecurityAccess_Level_EOL_Unlocked: operation=SecurityAccess_Level_EOL_Unlocked.SetSecurityAttemptCounter
            OpServerCallDcm_MainFunction_Start_RoutineServices_CheckEthernetIPPINGFunction: operation=RoutineServices_CheckEthernetIPPINGFunction.Start
            OpServerCallDcm_MainFunction_RequestResults_RoutineServices_CheckEthernetIPPINGFunction: operation=RoutineServices_CheckEthernetIPPINGFunction.RequestResults
            OpServerCallDcm_MainFunction_Start_RoutineServices_IVITouchTest: operation=RoutineServices_IVITouchTest.Start
            OpServerCallDcm_MainFunction_RequestResults_RoutineServices_IVITouchTest: operation=RoutineServices_IVITouchTest.RequestResults
            OpServerCallDcm_MainFunction_Start_RoutineServices_AVMRegister: operation=RoutineServices_AVMRegister.Start
            OpServerCallDcm_MainFunction_RequestResults_RoutineServices_AVMRegister: operation=RoutineServices_AVMRegister.RequestResults
            OpServerCallDcm_MainFunction_Start_RoutineServices_AMPCalibration: operation=RoutineServices_AMPCalibration.Start
            OpServerCallDcm_MainFunction_RequestResults_RoutineServices_AMPCalibration: operation=RoutineServices_AMPCalibration.RequestResults
            OpServerCallDcm_MainFunction_Start_RoutineServices_PhyTestMode: operation=RoutineServices_PhyTestMode.Start
            OpServerCallDcm_MainFunction_Start_RoutineServices_CableDiagnostics: operation=RoutineServices_CableDiagnostics.Start
            OpServerCallDcm_MainFunction_Start_RoutineServices_ResetSwitchStatistics: operation=RoutineServices_ResetSwitchStatistics.Start
            OpServerCallDcm_MainFunction_Start_RoutineServices_AVMEnvironmentCheck: operation=RoutineServices_AVMEnvironmentCheck.Start
            OpServerCallDcm_MainFunction_RequestResults_RoutineServices_AVMEnvironmentCheck: operation=RoutineServices_AVMEnvironmentCheck.RequestResults
            OpServerCallDcm_MainFunction_Start_RoutineServices_AVMAutoCalibration: operation=RoutineServices_AVMAutoCalibration.Start
            OpServerCallDcm_MainFunction_RequestResults_RoutineServices_AVMAutoCalibration: operation=RoutineServices_AVMAutoCalibration.RequestResults
            OpServerCallDcm_MainFunction_Start_RoutineServices_AVMManualCalibration: operation=RoutineServices_AVMManualCalibration.Start
            OpServerCallDcm_MainFunction_Stop_RoutineServices_AVMManualCalibration: operation=RoutineServices_AVMManualCalibration.Stop
            OpServerCallDcm_MainFunction_RequestResults_RoutineServices_AVMManualCalibration: operation=RoutineServices_AVMManualCalibration.RequestResults
            OpServerCallDcm_MainFunction_Start_RoutineServices_AVMManualViewSelect: operation=RoutineServices_AVMManualViewSelect.Start
            OpServerCallDcm_MainFunction_RequestResults_RoutineServices_AVMManualViewSelect: operation=RoutineServices_AVMManualViewSelect.RequestResults
            OpServerCallDcm_MainFunction_Start_RoutineServices_AVMManualConerSelect: operation=RoutineServices_AVMManualConerSelect.Start
            OpServerCallDcm_MainFunction_RequestResults_RoutineServices_AVMManualConerSelect: operation=RoutineServices_AVMManualConerSelect.RequestResults
            OpServerCallDcm_MainFunction_Start_RoutineServices_AVMManualConerMove: operation=RoutineServices_AVMManualConerMove.Start
            OpServerCallDcm_MainFunction_RequestResults_RoutineServices_AVMManualConerMove: operation=RoutineServices_AVMManualConerMove.RequestResults
            OpServerCallDcm_MainFunction_Start_RoutineServices_AVMManualCorrectValue: operation=RoutineServices_AVMManualCorrectValue.Start
            OpServerCallDcm_MainFunction_RequestResults_RoutineServices_AVMManualCorrectValue: operation=RoutineServices_AVMManualCorrectValue.RequestResults
            OpServerCallDcm_MainFunction_Start_RoutineServices_SystemRecovery: operation=RoutineServices_SystemRecovery.Start
            OpServerCallDcm_MainFunction_Start_RoutineServices_ODOReset: operation=RoutineServices_ODOReset.Start
            OpServerCallDcm_MainFunction_RequestResults_RoutineServices_ODOReset: operation=RoutineServices_ODOReset.RequestResults
            OpServerCallDcm_MainFunction_ReadData_DataServices_VehicleModel_VehicleModel: operation=DataServices_VehicleModel_VehicleModel.ReadData
            OpServerCallDcm_MainFunction_ConditionCheckRead_DataServices_VehicleModel_VehicleModel: operation=DataServices_VehicleModel_VehicleModel.ConditionCheckRead
            OpServerCallDcm_MainFunction_WriteData_DataServices_VehicleModel_VehicleModel: operation=DataServices_VehicleModel_VehicleModel.WriteData
            OpServerCallDcm_MainFunction_Start_RoutineServices_ConfigureFrontCamerParameters: operation=RoutineServices_ConfigureFrontCamerParameters.Start
            OpServerCallDcm_MainFunction_RequestResults_RoutineServices_ConfigureFrontCamerParameters: operation=RoutineServices_ConfigureFrontCamerParameters.RequestResults
            OpServerCallDcm_MainFunction_Start_RoutineServices_ConfigureRearCamerParameters: operation=RoutineServices_ConfigureRearCamerParameters.Start
            OpServerCallDcm_MainFunction_RequestResults_RoutineServices_ConfigureRearCamerParameters: operation=RoutineServices_ConfigureRearCamerParameters.RequestResults
            OpServerCallDcm_MainFunction_Start_RoutineServices_ConfigureLeftCamerParameters: operation=RoutineServices_ConfigureLeftCamerParameters.Start
            OpServerCallDcm_MainFunction_RequestResults_RoutineServices_ConfigureLeftCamerParameters: operation=RoutineServices_ConfigureLeftCamerParameters.RequestResults
            OpServerCallDcm_MainFunction_Start_RoutineServices_ConfigureRightCamerParameters: operation=RoutineServices_ConfigureRightCamerParameters.Start
            OpServerCallDcm_MainFunction_RequestResults_RoutineServices_ConfigureRightCamerParameters: operation=RoutineServices_ConfigureRightCamerParameters.RequestResults
            OpServerCallDcm_MainFunction_ReadDidData_DataServices_DIDRange_DidRangeEol1: operation=DataServices_DIDRange_DidRangeEol1.ReadDidData
            OpServerCallDcm_MainFunction_WriteDidData_DataServices_DIDRange_DidRangeEol1: operation=DataServices_DIDRange_DidRangeEol1.WriteDidData
            OpServerCallDcm_MainFunction_IsDidAvailable_DataServices_DIDRange_DidRangeEol1: operation=DataServices_DIDRange_DidRangeEol1.IsDidAvailable
            OpServerCallDcm_MainFunction_ReadDidData_DataServices_DIDRange_DidRangeDiag1: operation=DataServices_DIDRange_DidRangeDiag1.ReadDidData
            OpServerCallDcm_MainFunction_WriteDidData_DataServices_DIDRange_DidRangeDiag1: operation=DataServices_DIDRange_DidRangeDiag1.WriteDidData
            OpServerCallDcm_MainFunction_IsDidAvailable_DataServices_DIDRange_DidRangeDiag1: operation=DataServices_DIDRange_DidRangeDiag1.IsDidAvailable
            OpServerCallDcm_MainFunction_ReadDidData_DataServices_DIDRange_DidRangeDiag2: operation=DataServices_DIDRange_DidRangeDiag2.ReadDidData
            OpServerCallDcm_MainFunction_WriteDidData_DataServices_DIDRange_DidRangeDiag2: operation=DataServices_DIDRange_DidRangeDiag2.WriteDidData
            OpServerCallDcm_MainFunction_IsDidAvailable_DataServices_DIDRange_DidRangeDiag2: operation=DataServices_DIDRange_DidRangeDiag2.IsDidAvailable
            OpServerCallDcm_MainFunction_Start_RoutineServices_RequestCertificateStatus: operation=RoutineServices_RequestCertificateStatus.Start
            OpServerCallDcm_MainFunction_RequestResults_RoutineServices_RequestCertificateStatus: operation=RoutineServices_RequestCertificateStatus.RequestResults
        GetActiveProtocol: can-be-invoked-concurrently=true, symbol=Dcm_GetActiveProtocol
        GetSesCtrlType: can-be-invoked-concurrently=true, symbol=Dcm_GetSesCtrlType
        ResetToDefaultSession: can-be-invoked-concurrently=true, symbol=Dcm_ResetToDefaultSession
        GetSecurityLevel: can-be-invoked-concurrently=true, symbol=Dcm_GetSecurityLevel
        SetActiveDiagnostic: can-be-invoked-concurrently=true, symbol=Dcm_SetActiveDiagnostic
        GetRequestKind: can-be-invoked-concurrently=true, symbol=Dcm_GetRequestKind
  swc implementation DcmImplementation: programming-language=C, behavior=DcmInternalBehavior
